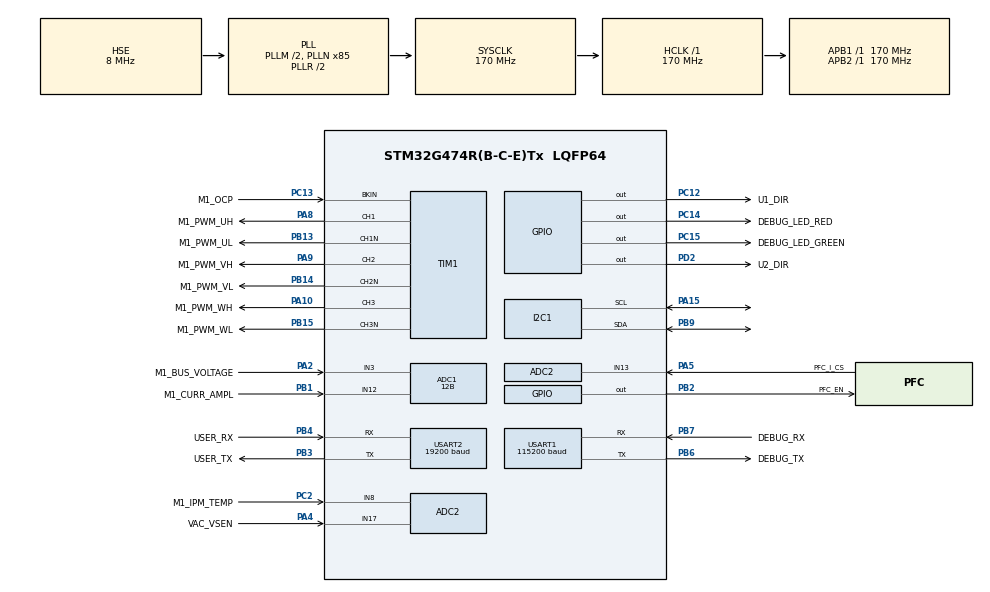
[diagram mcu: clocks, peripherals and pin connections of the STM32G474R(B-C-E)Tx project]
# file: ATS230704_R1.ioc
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ADC1.Channel-1\#ChannelRegularConversion=ADC_CHANNEL_3
ADC1.ClockPrescaler=ADC_CLOCK_ASYNC_DIV1
ADC1.ContinuousConvMode=DISABLE
ADC1.DMAContinuousRequests=DISABLE
ADC1.DataAlign=ADC_DATAALIGN_LEFT
ADC1.DiscontinuousConvMode=DISABLE
ADC1.EOCSelection=ADC_EOC_SINGLE_CONV
ADC1.EnableAnalogWatchDog1=false
ADC1.EnableAnalogWatchDog2=false
ADC1.EnableAnalogWatchDog3=false
ADC1.EnableInjectedConversion=ENABLE
ADC1.EnableRegularConversion=ENABLE
ADC1.ExternalTrigConv=ADC_SOFTWARE_START
ADC1.ExternalTrigConvEdge=ADC_EXTERNALTRIGCONVEDGE_NONE
ADC1.ExternalTrigInjecConv=ADC_EXTERNALTRIGINJEC_T1_TRGO
ADC1.ExternalTrigInjecConvEdge=ADC_EXTERNALTRIGINJECCONV_EDGE_RISINGFALLING
ADC1.InjNumberOfConversion=2
ADC1.InjectedChannel-1\#ChannelInjectedConversion=ADC_CHANNEL_12
ADC1.InjectedChannel-2\#ChannelInjectedConversion=ADC_CHANNEL_12
ADC1.InjectedConvMode=None
ADC1.InjectedOffset-1\#ChannelInjectedConversion=0
ADC1.InjectedOffset-2\#ChannelInjectedConversion=0
ADC1.InjectedOffsetNumber-1\#ChannelInjectedConversion=ADC_OFFSET_NONE
ADC1.InjectedOffsetNumber-2\#ChannelInjectedConversion=ADC_OFFSET_NONE
ADC1.InjectedRank-1\#ChannelInjectedConversion=1
ADC1.InjectedRank-2\#ChannelInjectedConversion=2
ADC1.InjectedSamplingTime-1\#ChannelInjectedConversion=ADC_SAMPLETIME_6CYCLES_5
ADC1.InjectedSamplingTime-2\#ChannelInjectedConversion=ADC_SAMPLETIME_6CYCLES_5
ADC1.LowPowerAutoWait=DISABLE
ADC1.NbrOfConversion=1
ADC1.NbrOfConversionFlag=1
ADC1.Offset-1\#ChannelRegularConversion=0
ADC1.OffsetNumber-1\#ChannelRegularConversion=ADC_OFFSET_NONE
ADC1.Overrun=ADC_OVR_DATA_PRESERVED
ADC1.Rank-1\#ChannelRegularConversion=1
ADC1.Resolution=ADC_RESOLUTION_12B
ADC1.SamplingTime-1\#ChannelRegularConversion=ADC_SAMPLETIME_640CYCLES_5
ADC1.ScanConvMode=ADC_SCAN_ENABLE
ADC1.master=1
ADC2.Channel-0\#ChannelRegularConversion=ADC_CHANNEL_8
ADC2.Channel-1\#ChannelRegularConversion=ADC_CHANNEL_13
ADC2.Channel-2\#ChannelRegularConversion=ADC_CHANNEL_17
ADC2.ClockPrescaler=ADC_CLOCK_ASYNC_DIV1
ADC2.ContinuousConvMode=ENABLE
ADC2.DMAContinuousRequests=ENABLE
ADC2.NbrOfConversion=3
ADC2.NbrOfConversionFlag=1
ADC2.OffsetNumber-0\#ChannelRegularConversion=ADC_OFFSET_NONE
ADC2.OffsetNumber-1\#ChannelRegularConversion=ADC_OFFSET_NONE
ADC2.OffsetNumber-2\#ChannelRegularConversion=ADC_OFFSET_NONE
ADC2.Rank-0\#ChannelRegularConversion=1
ADC2.Rank-1\#ChannelRegularConversion=2
ADC2.Rank-2\#ChannelRegularConversion=3
ADC2.SamplingTime-0\#ChannelRegularConversion=ADC_SAMPLETIME_2CYCLES_5
ADC2.SamplingTime-1\#ChannelRegularConversion=ADC_SAMPLETIME_2CYCLES_5
ADC2.SamplingTime-2\#ChannelRegularConversion=ADC_SAMPLETIME_2CYCLES_5
ADC3.Channel-0\#ChannelRegularConversion=ADC_CHANNEL_1
ADC3.NbrOfConversionFlag=1
ADC3.OffsetNumber-0\#ChannelRegularConversion=ADC_OFFSET_NONE
ADC3.Rank-0\#ChannelRegularConversion=1
ADC3.SamplingTime-0\#ChannelRegularConversion=ADC_SAMPLETIME_2CYCLES_5
ADC3.master=1
Dma.ADC2.5.Direction=DMA_PERIPH_TO_MEMORY
Dma.ADC2.5.EventEnable=DISABLE
Dma.ADC2.5.Instance=DMA1_Channel6
Dma.ADC2.5.MemDataAlignment=DMA_MDATAALIGN_WORD
Dma.ADC2.5.MemInc=DMA_MINC_ENABLE
Dma.ADC2.5.Mode=DMA_CIRCULAR
Dma.ADC2.5.PeriphDataAlignment=DMA_PDATAALIGN_WORD
Dma.ADC2.5.PeriphInc=DMA_PINC_DISABLE
Dma.ADC2.5.Polarity=HAL_DMAMUX_REQ_GEN_RISING
Dma.ADC2.5.Priority=DMA_PRIORITY_LOW
Dma.ADC2.5.RequestNumber=1
Dma.ADC2.5.SignalID=NONE
Dma.ADC2.5.SyncEnable=DISABLE
Dma.ADC2.5.SyncPolarity=HAL_DMAMUX_SYNC_NO_EVENT
Dma.ADC2.5.SyncRequestNumber=1
Dma.ADC2.5.SyncSignalID=NONE
Dma.Request0=TIM1_CH4
Dma.Request1=USART1_RX
Dma.Request2=USART1_TX
Dma.Request3=USART2_TX
Dma.Request4=USART2_RX
Dma.Request5=ADC2
Dma.TIM1_CH4.0.Direction=DMA_MEMORY_TO_PERIPH
Dma.TIM1_CH4.0.EventEnable=DISABLE
Dma.TIM1_CH4.0.Instance=DMA1_Channel1
Dma.TIM1_CH4.0.MemDataAlignment=DMA_MDATAALIGN_HALFWORD
Dma.TIM1_CH4.0.MemInc=DMA_MINC_ENABLE
Dma.TIM1_CH4.0.Mode=DMA_CIRCULAR
Dma.TIM1_CH4.0.PeriphDataAlignment=DMA_PDATAALIGN_HALFWORD
Dma.TIM1_CH4.0.PeriphInc=DMA_PINC_DISABLE
Dma.TIM1_CH4.0.Polarity=HAL_DMAMUX_REQ_GEN_RISING
Dma.TIM1_CH4.0.Priority=DMA_PRIORITY_HIGH
Dma.TIM1_CH4.0.RequestNumber=1
Dma.TIM1_CH4.0.SignalID=NONE
Dma.TIM1_CH4.0.SyncEnable=DISABLE
Dma.TIM1_CH4.0.SyncPolarity=HAL_DMAMUX_SYNC_NO_EVENT
Dma.TIM1_CH4.0.SyncRequestNumber=1
Dma.TIM1_CH4.0.SyncSignalID=NONE
Dma.USART1_RX.1.Direction=DMA_PERIPH_TO_MEMORY
Dma.USART1_RX.1.EventEnable=DISABLE
Dma.USART1_RX.1.Instance=DMA1_Channel2
Dma.USART1_RX.1.MemDataAlignment=DMA_MDATAALIGN_BYTE
Dma.USART1_RX.1.MemInc=DMA_MINC_ENABLE
Dma.USART1_RX.1.Mode=DMA_NORMAL
Dma.USART1_RX.1.PeriphDataAlignment=DMA_PDATAALIGN_BYTE
Dma.USART1_RX.1.PeriphInc=DMA_PINC_DISABLE
Dma.USART1_RX.1.Polarity=HAL_DMAMUX_REQ_GEN_RISING
Dma.USART1_RX.1.Priority=DMA_PRIORITY_LOW
Dma.USART1_RX.1.RequestNumber=1
Dma.USART1_RX.1.SignalID=NONE
Dma.USART1_RX.1.SyncEnable=DISABLE
Dma.USART1_RX.1.SyncPolarity=HAL_DMAMUX_SYNC_NO_EVENT
Dma.USART1_RX.1.SyncRequestNumber=1
Dma.USART1_RX.1.SyncSignalID=NONE
Dma.USART1_TX.2.Direction=DMA_MEMORY_TO_PERIPH
Dma.USART1_TX.2.EventEnable=DISABLE
Dma.USART1_TX.2.Instance=DMA1_Channel3
Dma.USART1_TX.2.MemDataAlignment=DMA_MDATAALIGN_BYTE
Dma.USART1_TX.2.MemInc=DMA_MINC_ENABLE
Dma.USART1_TX.2.Mode=DMA_NORMAL
Dma.USART1_TX.2.PeriphDataAlignment=DMA_PDATAALIGN_BYTE
Dma.USART1_TX.2.PeriphInc=DMA_PINC_DISABLE
Dma.USART1_TX.2.Polarity=HAL_DMAMUX_REQ_GEN_RISING
Dma.USART1_TX.2.Priority=DMA_PRIORITY_LOW
Dma.USART1_TX.2.RequestNumber=1
Dma.USART1_TX.2.SignalID=NONE
Dma.USART1_TX.2.SyncEnable=DISABLE
Dma.USART1_TX.2.SyncPolarity=HAL_DMAMUX_SYNC_NO_EVENT
Dma.USART1_TX.2.SyncRequestNumber=1
Dma.USART1_TX.2.SyncSignalID=NONE
Dma.USART2_RX.4.Direction=DMA_PERIPH_TO_MEMORY
Dma.USART2_RX.4.EventEnable=DISABLE
Dma.USART2_RX.4.Instance=DMA1_Channel5
Dma.USART2_RX.4.MemDataAlignment=DMA_MDATAALIGN_BYTE
Dma.USART2_RX.4.MemInc=DMA_MINC_ENABLE
Dma.USART2_RX.4.Mode=DMA_CIRCULAR
Dma.USART2_RX.4.PeriphDataAlignment=DMA_PDATAALIGN_BYTE
Dma.USART2_RX.4.PeriphInc=DMA_PINC_DISABLE
Dma.USART2_RX.4.Polarity=HAL_DMAMUX_REQ_GEN_RISING
Dma.USART2_RX.4.Priority=DMA_PRIORITY_LOW
Dma.USART2_RX.4.RequestNumber=1
Dma.USART2_RX.4.SignalID=NONE
Dma.USART2_RX.4.SyncEnable=DISABLE
Dma.USART2_RX.4.SyncPolarity=HAL_DMAMUX_SYNC_NO_EVENT
Dma.USART2_RX.4.SyncRequestNumber=1
Dma.USART2_RX.4.SyncSignalID=NONE
Dma.USART2_TX.3.Direction=DMA_MEMORY_TO_PERIPH
Dma.USART2_TX.3.EventEnable=DISABLE
Dma.USART2_TX.3.Instance=DMA1_Channel4
Dma.USART2_TX.3.MemDataAlignment=DMA_MDATAALIGN_BYTE
Dma.USART2_TX.3.MemInc=DMA_MINC_ENABLE
Dma.USART2_TX.3.Mode=DMA_NORMAL
Dma.USART2_TX.3.PeriphDataAlignment=DMA_PDATAALIGN_BYTE
Dma.USART2_TX.3.PeriphInc=DMA_PINC_DISABLE
Dma.USART2_TX.3.Polarity=HAL_DMAMUX_REQ_GEN_RISING
Dma.USART2_TX.3.Priority=DMA_PRIORITY_LOW
Dma.USART2_TX.3.RequestNumber=1
Dma.USART2_TX.3.SignalID=NONE
Dma.USART2_TX.3.SyncEnable=DISABLE
Dma.USART2_TX.3.SyncPolarity=HAL_DMAMUX_SYNC_NO_EVENT
Dma.USART2_TX.3.SyncRequestNumber=1
Dma.USART2_TX.3.SyncSignalID=NONE
ExtraMW=MotorControl
ExtraMW.MotorControl.Config=MotorControl
ExtraMW.MotorControl.Mode=MotorControl
ExtraMW.MotorControl.Root=MCSDK_v6.2.0-Full/MotorControl
ExtraMW.MotorControl.Template=templates
FREERTOS.Tasks01=Print_Task,8,256,StartPrintTask,As weak,NULL,Static,PrintTaskBuffer,PrintTaskControlBlock;Modbus_Task,40,128,StartModbusTask,As weak,NULL,Static,Modbus_TaskBuffer,Modbus_TaskControlBlock;Sensor_TasK,24,128,StartSensorTask,As weak,NULL,Static,Sensor_TasKBuffer,Sensor_TasKControlBlock;PowerCTRLTask,40,128,StartPowerCTRLTask,As weak,NULL,Static,PowerCTRLTaskBuffer,PowerCTRLTaskControlBlock
FREERTOS.configCHECK_FOR_STACK_OVERFLOW=2
FREERTOS.configUSE_NEWLIB_REENTRANT=1
I2C1.Timing=0x30A0A7FB
Mcu.Family=STM32G4
Mcu.Name=STM32G474R(B-C-E)Tx
Mcu.Package=LQFP64
MotorControl.ADC_AHBPERIPH=RCC_AHBPeriph_ADC1
MotorControl.ADC_CLOCK_WB_DIV=1
MotorControl.ADC_PERIPH=ADC1
MotorControl.ADC_REFERENCE_VOLTAGE=3.3
MotorControl.BOARD=NUCLEO-G474RE
MotorControl.BUS_VOLTAGE_READING=true
MotorControl.CCMRAM_ENABLED=false
MotorControl.CLOCK_FREQUENCY=CPU_CLK_170_MHZ
MotorControl.CLOCK_SOURCE=EXTERNAL
MotorControl.CPU_CLK_170_MHZ=true
MotorControl.CTLBOARD_NAME=NUCLEO-G474RE
MotorControl.CUBE_MX_VER=6.9.2
MotorControl.CURRENT_READING_TOPOLOGY=SINGLE_SHUNT
MotorControl.CURR_SAMPLING_TIME=6
MotorControl.DBG_MCU_LOAD_MEASURE=true
MotorControl.DEBUG_DAC_FUNCTIONALITY_EN=false
MotorControl.DISSIPATIVE_BRAKE_POLARITY=DOUT_ACTIVE_HIGH
MotorControl.DRIVES_NUMBER_SELECTION=SINGLEDRIVE
MotorControl.DRIVE_NUMBER=1
MotorControl.DRIVE_TYPE=FOC
MotorControl.EMERGENCY_STOP_GPIO_PIN=LL_GPIO_PIN_13
MotorControl.EMERGENCY_STOP_GPIO_PORT=GPIOC
MotorControl.ENCODER_AVAILABLE=false
MotorControl.ENCODER_PPR=400
MotorControl.EXT_CLK_8_MHZ=true
MotorControl.EXT_CLOCK_FREQUENCY=EXT_CLK_8_MHZ
MotorControl.FEEDBACK_NET_FILTERING=false
MotorControl.HALL_SENSORS_AVAILABLE=false
MotorControl.HIGH_SIDE_IDLE_STATE=false
MotorControl.HWV_CS=SingleShunt_AmplifiedCurrents
MotorControl.HWV_OCP=OnPowerStageOCP
MotorControl.HWV_PWM=DrivingHighAndLowSides
MotorControl.HW_COMPLEMENTED_LOW_SIDE=false
MotorControl.HW_DEAD_TIME_NS=8000
MotorControl.IPs=CORDIC,SYS,NVIC,RCC,MotorControl,TIM1,ADC1,USART1,DMA
MotorControl.LOW_MEMORY_FOOTPRINT_REG=false
MotorControl.LOW_SIDE_IDLE_STATE=false
MotorControl.LOW_SIDE_SIGNALS_ENABLING=LS_PWM_TIMER
MotorControl.M1_AMPLIFICATION_GAIN=2.941176471
MotorControl.M1_ANGC={-773,-2329,-3874,-5379,-6858,-8285,-9684,-11001}
MotorControl.M1_AUXILIARY_SPEED_SENSOR=NONE
MotorControl.M1_BEMF_CONSISTENCY_GAIN=64
MotorControl.M1_BEMF_CONSISTENCY_TOL=64
MotorControl.M1_BOARD_MAX_CURRENT=25.0
MotorControl.M1_BUS_VOLTAGE_READING=true
MotorControl.M1_CONSTANT1_D=164333
MotorControl.M1_CONSTANT1_Q=234761
MotorControl.M1_CONSTANT2_QD=42544
MotorControl.M1_CS_ADC_NUM=1
MotorControl.M1_CS_ADC_PHASE_SHARED=NONE
MotorControl.M1_CS_ADC_U=ADC1
MotorControl.M1_CS_CHANNEL_U=12
MotorControl.M1_CURRENT_AMPLIFICATION_TOPO=EXTERNAL
MotorControl.M1_CURRENT_SENSING_TOPO=SINGLE_SHUNT_PHASE_SHIFT
MotorControl.M1_CURR_SAMPLING_TIME=6
MotorControl.M1_DBG_OPEN_LOOP_ENABLE=false
MotorControl.M1_DC_CURRENT_RS_MEAS=20.0
MotorControl.M1_DEFAULT_CONTROL_MODE=STC_SPEED_MODE
MotorControl.M1_DEFAULT_FLUX_COMPONENT=0
MotorControl.M1_DEFAULT_TARGET_SPEED_RPM=1300
MotorControl.M1_DEFAULT_TORQUE_COMPONENT=0
MotorControl.M1_DISCONTINUOUS_PWM=false
MotorControl.M1_DISSIPATIVE_BRAKE_POLARITY=DOUT_ACTIVE_HIGH
MotorControl.M1_DP_TOPOLOGY=NONE
MotorControl.M1_DRIVE_TYPE=FOC
MotorControl.M1_ENABLE_SL_ALGO_FROM_PHASE=4
MotorControl.M1_ENCODER_PPR=400
MotorControl.M1_F1=16384
MotorControl.M1_F2=8192
MotorControl.M1_FEED_FORWARD_CURRENT_REG_ENABLING=false
MotorControl.M1_FLUX_WEAKENING_ENABLING=true
MotorControl.M1_FW_KIDIV=32768
MotorControl.M1_FW_KI_GAIN=5000
MotorControl.M1_FW_KPDIV=32768
MotorControl.M1_FW_KP_GAIN=3000
MotorControl.M1_FW_VOLTAGE_REF=985
MotorControl.M1_GAIN1=-24494
MotorControl.M1_GAIN2=24912
MotorControl.M1_HALL_PHASE_SHIFT=300
MotorControl.M1_HALL_SENSORS_PLACEMENT=DEGREES_120
MotorControl.M1_HIGH_SIDE_IDLE_STATE=false
MotorControl.M1_HW_DEAD_TIME_NS=8000
MotorControl.M1_ICL_ENABLED=false
MotorControl.M1_ID_DEMAG=-25
MotorControl.M1_IQMAX=24.58797507430251
MotorControl.M1_LDLQ_RATIO=0.700
MotorControl.M1_LOW_SIDE_IDLE_STATE=false
MotorControl.M1_LOW_SIDE_SIGNALS_ENABLING=LS_PWM_TIMER
MotorControl.M1_LS=0.00466
MotorControl.M1_MAX_APPLICATION_SPEED=5400
MotorControl.M1_MAX_MODULATION_INDEX=100
MotorControl.M1_MIN_APPLICATION_SPEED=0
MotorControl.M1_MOTOR_MAX_SPEED_RPM=5400
MotorControl.M1_MOTOR_NAME=BTH420SDPC9EQA
MotorControl.M1_MOTOR_RATED_FLUX=1.055730079
MotorControl.M1_MOTOR_VOLTAGE_CONSTANT=43.1
MotorControl.M1_MTPA_ENABLING=true
MotorControl.M1_NB_CONSECUTIVE_TESTS=3
MotorControl.M1_NOMINAL_BUS_VOLTAGE_V=400
MotorControl.M1_NOMINAL_CURRENT=20.0
MotorControl.M1_OBS_MINIMUM_SPEED_RPM=850
MotorControl.M1_OCP_BKIN_FILTER=3
MotorControl.M1_OCP_BKIN_MODE=EXT_MODE
MotorControl.M1_OCP_BKIN_POLARITY=EMSTOP_ACTIVE_LOW
MotorControl.M1_OCP_DESTINATION=TIM_BKIN
MotorControl.M1_OCP_TOPOLOGY=EXTERNAL
MotorControl.M1_OFST={0,144,432,853,1404,2069,2851,3709}
MotorControl.M1_OVERMODULATION=false
MotorControl.M1_OVP_THRESHOLD_LOW=400
MotorControl.M1_OV_VOLTAGE_PROT_ENABLING=false
MotorControl.M1_PHASE1_DURATION=300
MotorControl.M1_PHASE1_FINAL_CURRENT=5
MotorControl.M1_PHASE1_FINAL_SPEED_RPM=0
MotorControl.M1_PHASE2_DURATION=500
MotorControl.M1_PHASE2_FINAL_CURRENT=5
MotorControl.M1_PHASE2_FINAL_SPEED_RPM=0
MotorControl.M1_PHASE3_DURATION=0
MotorControl.M1_PHASE3_FINAL_CURRENT=5
MotorControl.M1_PHASE3_FINAL_SPEED_RPM=500
MotorControl.M1_PHASE4_DURATION=5000
MotorControl.M1_PHASE4_FINAL_CURRENT=5
MotorControl.M1_PHASE4_FINAL_SPEED_RPM=900
MotorControl.M1_PHASE5_DURATION=20000
MotorControl.M1_PHASE5_FINAL_CURRENT=5
MotorControl.M1_PHASE5_FINAL_SPEED_RPM=1300
MotorControl.M1_PID_FLUX_KD_DEFAULT=100
MotorControl.M1_PID_FLUX_KI_DEFAULT=63
MotorControl.M1_PID_FLUX_KP_DEFAULT=1703
MotorControl.M1_PID_SPEED_KD_DEFAULT=0
MotorControl.M1_PID_SPEED_KI_DEFAULT=811
MotorControl.M1_PID_SPEED_KP_DEFAULT=3166
MotorControl.M1_PID_TORQUE_KD_DEFAULT=100
MotorControl.M1_PID_TORQUE_KI_DEFAULT=63
MotorControl.M1_PID_TORQUE_KP_DEFAULT=2361
MotorControl.M1_PLL_KI_GAIN=64
MotorControl.M1_PLL_KP_GAIN=718
MotorControl.M1_POLE_PAIR_NUM=2
MotorControl.M1_POSITION_CTRL_ENABLING=false
MotorControl.M1_POTENTIOMETER_ENABLE=false
MotorControl.M1_POWERBOARD_NAME=ATS230704-R1
MotorControl.M1_PWM_CHARGE_BOOT_CAP_DUTY_CYCLES=0.000
MotorControl.M1_PWM_CHARGE_BOOT_CAP_MS=10
MotorControl.M1_PWM_DRIVER_PN=L6390D
MotorControl.M1_PWM_FREQUENCY=8000
MotorControl.M1_PWM_TIMER_BRK_IRQ=TIM1_BRK_TIM15
MotorControl.M1_PWM_TIMER_SELECTION=PWM_TIM1
MotorControl.M1_PWM_TIMER_UP_IRQ=TIM1_UP_TIM16
MotorControl.M1_REGULATION_EXECUTION_RATE=1
MotorControl.M1_RS=0.25
MotorControl.M1_RSHUNT=0.01175
MotorControl.M1_SEGDIV=3052
MotorControl.M1_SHARED_SIGNAL_ENABLE=false
MotorControl.M1_SPD_DIFFERENTIAL_TERM_ENABLING=false
MotorControl.M1_SPEED_BAND_LOWER_LIMIT=16
MotorControl.M1_SPEED_BAND_UPPER_LIMIT=22
MotorControl.M1_SPEED_FEEDBACK_CHECK=true
MotorControl.M1_SPEED_LOOP_FREQUENCY_HZ=500
MotorControl.M1_SPEED_SENSOR=STO_PLL
MotorControl.M1_SP_KDDIV=16
MotorControl.M1_SP_KIDIV=16384
MotorControl.M1_SP_KPDIV=128
MotorControl.M1_SS_MEAS_ERRORS_BEFORE_FAULTS=100
MotorControl.M1_STARTING_ANGLE_DEG=0
MotorControl.M1_STO_FIFO_DEPTH_01HZ=64
MotorControl.M1_STO_FIFO_DEPTH_DPP=64
MotorControl.M1_SW_DEADTIME_NS=4000
MotorControl.M1_TEMPERATURE_READING=false
MotorControl.M1_TF_KDDIV=8192
MotorControl.M1_TF_KIDIV=16384
MotorControl.M1_TF_KPDIV=4096
MotorControl.M1_TNOISE_NS=2500
MotorControl.M1_TRANSITION_DURATION=0
MotorControl.M1_TRISE_NS=2500
MotorControl.M1_USE_INTERNAL_OPAMP=false
MotorControl.M1_UV_VOLTAGE_PROT_ENABLING=false
MotorControl.M1_VARIANCE_THRESHOLD=0.25
MotorControl.M1_VBUS_ADC=ADC1
MotorControl.M1_VBUS_ADC_SAMPLING_TIME=640
MotorControl.M1_VBUS_CHANNEL=ADC_CHANNEL_3
MotorControl.M1_VBUS_PARTITIONING_FACTOR=0.006493506493506494
MotorControl.MAX_READABLE_CURRENT=23.179
MotorControl.MCP_ASPEP_OVER_UART=true
MotorControl.MCP_ASYNC_EN=false
MotorControl.MCP_ASYNC_OVER_ASPEP_EN=false
MotorControl.MCP_ASYNC_OVER_UART_A_EN=false
MotorControl.MCP_DMACH_RX_UART_A=2
MotorControl.MCP_DMACH_TX_UART_A=3
MotorControl.MCP_DMA_RX_UART_A=DMA1
MotorControl.MCP_DMA_TX_UART_A=DMA1
MotorControl.MCP_EN=true
MotorControl.MCP_IRQ_HANDLER_DMA_RX_UART_A=DMA1_Channel2_IRQHandler
MotorControl.MCP_IRQ_HANDLER_UART_A=USART1_IRQHandler
MotorControl.MCP_OVER_ASPEP_EN=true
MotorControl.MCP_OVER_STLNK_EN=false
MotorControl.MCP_OVER_UART_A_EN=true
MotorControl.MCP_OVER_UART_B_EN=false
MotorControl.MCP_RX_SYNC_PAYLOAD_MAX=128
MotorControl.MCP_TX_SYNC_PAYLOAD_MAX=128
MotorControl.MCU=STM32G474RE
MotorControl.MCU_FAMILY=STM32G4
MotorControl.MCU_LINE=STM32G4x4
MotorControl.MCU_NAME=STM32G474R(B-C-E)Tx
MotorControl.MCU_PACKAGE=LQFP64
MotorControl.MCU_TYPE=STM32G474RE
MotorControl.MCU_USERNAME=STM32G474RETx
MotorControl.MC_WORKBENCH_VERSION=6.2.0
MotorControl.MOTOR_PROFILER=false
MotorControl.MOTOR_TYPE=PMSM
MotorControl.OV_VOLTAGE_PROT_ENABLING=false
MotorControl.PHASE_CURRENTS_ADC=ADC1
MotorControl.PHASE_CURRENTS_CHANNEL=ADC_CHANNEL_12
MotorControl.PHASE_CURRENTS_GPIO_PIN=LL_GPIO_PIN_1
MotorControl.PHASE_CURRENTS_GPIO_PORT=GPIOB
MotorControl.PHASE_UH_GPIO_PIN=LL_GPIO_PIN_8
MotorControl.PHASE_UH_GPIO_PORT=GPIOA
MotorControl.PHASE_UH_POLARITY=H_ACTIVE_HIGH
MotorControl.PHASE_UL_GPIO_PIN=LL_GPIO_PIN_13
MotorControl.PHASE_UL_GPIO_PORT=GPIOB
MotorControl.PHASE_UL_POLARITY=L_ACTIVE_HIGH
MotorControl.PHASE_VH_GPIO_PIN=LL_GPIO_PIN_9
MotorControl.PHASE_VH_GPIO_PORT=GPIOA
MotorControl.PHASE_VH_POLARITY=H_ACTIVE_HIGH
MotorControl.PHASE_VL_GPIO_PIN=LL_GPIO_PIN_14
MotorControl.PHASE_VL_GPIO_PORT=GPIOB
MotorControl.PHASE_VL_POLARITY=L_ACTIVE_HIGH
MotorControl.PHASE_WH_GPIO_PIN=LL_GPIO_PIN_10
MotorControl.PHASE_WH_GPIO_PORT=GPIOA
MotorControl.PHASE_WH_POLARITY=H_ACTIVE_HIGH
MotorControl.PHASE_WL_GPIO_PIN=LL_GPIO_PIN_15
MotorControl.PHASE_WL_GPIO_PORT=GPIOB
MotorControl.PHASE_WL_POLARITY=L_ACTIVE_HIGH
MotorControl.POTENTIOMETER_READING=false
MotorControl.PWM_FREQUENCY=10000
MotorControl.PWM_TIMER_SELECTION=PWM_TIM1
MotorControl.REGULATION_EXECUTION_RATE=1
MotorControl.RTOS=NONE
MotorControl.R_BRAKE_GPIO_PIN=LL_GPIO_PIN_11
MotorControl.R_BRAKE_GPIO_PORT=GPIOC
MotorControl.SINGLEDRIVE=true
MotorControl.SINGLE_SHUNT=true
MotorControl.SPD_DIFFERENTIAL_TERM_ENABLING=false
MotorControl.SPEED_SENSOR_SELECTION=STATE_OBSERVER_PLL
MotorControl.START_STOP_BTN=false
MotorControl.STATE_OBSERVER_PLL=true
MotorControl.STM32G474RE=true
MotorControl.SW_DEADTIME_NS=3000
MotorControl.TEMPERATURE_READING=false
MotorControl.TFDIFFERENTIAL_TERM_ENABLING=false
MotorControl.TRISE_NS=4500
MotorControl.USART_RX_GPIO_PIN=LL_GPIO_PIN_7
MotorControl.USART_RX_GPIO_PORT=GPIOB
MotorControl.USART_SELECTION=USE_USART1
MotorControl.USART_SELECTION_A=USART1
MotorControl.USART_SPEED=115200
MotorControl.USART_TX_GPIO_PIN=LL_GPIO_PIN_6
MotorControl.USART_TX_GPIO_PORT=GPIOB
MotorControl.USE_3OPAMPS=false
MotorControl.USE_INTERNAL_OPAMP=false
MotorControl.UV_VOLTAGE_PROT_ENABLING=false
MotorControl.VBUS_ADC=ADC1
MotorControl.VBUS_ADC_SAMPLING_TIME=640
MotorControl.VBUS_CHANNEL=ADC_CHANNEL_3
MotorControl.VBUS_GPIO_PIN=LL_GPIO_PIN_2
MotorControl.VBUS_GPIO_PORT=GPIOA
MotorControl.WB_UI_CUTOFF_FREQUENCY=1500
MotorControl.WB_UI_ENCODER_HAS_INDEX_PIN=false
MotorControl.WB_UI_FLUX_TARGET=0
MotorControl.WB_UI_FRICTION=666
MotorControl.WB_UI_INERTIA=666
MotorControl.WB_UI_MAGNETIC_STRUCTURE=I-PMSM
MotorControl.WB_UI_MAX_CURRENT=25.0
MotorControl.WB_UI_MAX_NOMINAL_DC_VOLTAGE=400
MotorControl.WB_UI_MOTOR_DESCRIPTION=Motor high voltage
MotorControl.WB_UI_OCP_DISABLING_ENABLE=false
MotorControl.WB_UI_OCP_THRESHOLD=24
MotorControl.WB_UI_PW_BOARD_MAX_RATED_CURRENT=25.0
MotorControl.WB_UI_PW_BOARD_MAX_VOLTAGE=400
MotorControl.WB_UI_PW_BOARD_MIN_VOLTAGE=18
MotorControl.WB_UI_VPOL=1.65
MotorControl.WB_to_Mx_template_version=23-09-08
MotorControl.WB_to_Mx_version=6.2.0
NVIC.ADC1_2_IRQn=true\:2\:0\:true\:true\:false\:4\:false\:true\:true\:true
NVIC.DMA1_Channel1_IRQn=true\:0\:0\:true\:true\:false\:2\:false\:true\:true\:true
NVIC.DMA1_Channel2_IRQn=true\:3\:0\:true\:true\:false\:3\:false\:true\:true\:true
NVIC.DMA1_Channel4_IRQn=true\:3\:0\:true\:false\:true\:false\:true\:true\:true
NVIC.DMA1_Channel5_IRQn=true\:3\:0\:true\:false\:true\:false\:true\:true\:true
NVIC.PriorityGroup=NVIC_PRIORITYGROUP_4
NVIC.TIM1_BRK_TIM15_IRQn=true\:4\:0\:true\:true\:false\:5\:false\:true\:true\:true
NVIC.TIM1_UP_TIM16_IRQn=true\:0\:0\:true\:true\:false\:6\:false\:true\:true\:true
NVIC.TIM6_DAC_IRQn=true\:15\:0\:true\:true\:true\:7\:true\:true\:true\:true
NVIC.USART1_IRQn=true\:3\:0\:true\:true\:false\:1\:false\:true\:true\:true
NVIC.USART2_IRQn=true\:3\:0\:true\:false\:true\:false\:true\:true\:true
PA10.GPIO_Label=M1_PWM_WH
PA10.GPIO_PuPd=GPIO_PULLDOWN
PA10.GPIO_Speed=GPIO_SPEED_FREQ_HIGH
PA10.Signal=S_TIM1_CH3
PA13.GPIO_Label=TMS
PA13.Mode=Serial_Wire
PA13.Signal=SYS_JTMS-SWDIO
PA14.GPIO_Label=TCK
PA14.Mode=Serial_Wire
PA14.Signal=SYS_JTCK-SWCLK
PA15.Mode=I2C
PA15.Signal=I2C1_SCL
PA2.GPIO_Label=M1_BUS_VOLTAGE
PA2.Mode=IN3-Single-Ended
PA2.Signal=ADC1_IN3
PA4.GPIO_Label=VAC_VSEN
PA4.Mode=IN17-Single-Ended
PA4.Signal=ADC2_IN17
PA5.GPIO_Label=PFC_I_CS
PA5.Mode=IN13-Single-Ended
PA5.Signal=ADC2_IN13
PA8.GPIO_Label=M1_PWM_UH
PA8.GPIO_PuPd=GPIO_PULLDOWN
PA8.GPIO_Speed=GPIO_SPEED_FREQ_HIGH
PA8.Signal=S_TIM1_CH1
PA9.GPIO_Label=M1_PWM_VH
PA9.GPIO_PuPd=GPIO_PULLDOWN
PA9.GPIO_Speed=GPIO_SPEED_FREQ_HIGH
PA9.Signal=S_TIM1_CH2
PB1.GPIO_Label=M1_CURR_AMPL
PB1.Signal=SharedAnalog_PB1
PB13.GPIO_Label=M1_PWM_UL
PB13.GPIO_PuPd=GPIO_PULLDOWN
PB13.GPIO_Speed=GPIO_SPEED_FREQ_HIGH
PB13.Mode=PWM Generation1 CH1 CH1N
PB13.Signal=TIM1_CH1N
PB14.GPIO_Label=M1_PWM_VL
PB14.GPIO_PuPd=GPIO_PULLDOWN
PB14.GPIO_Speed=GPIO_SPEED_FREQ_HIGH
PB14.Mode=PWM Generation2 CH2 CH2N
PB14.Signal=TIM1_CH2N
PB15.GPIO_Label=M1_PWM_WL
PB15.GPIO_PuPd=GPIO_PULLDOWN
PB15.GPIO_Speed=GPIO_SPEED_FREQ_HIGH
PB15.Mode=PWM Generation3 CH3 CH3N
PB15.Signal=TIM1_CH3N
PB2.GPIO_Label=PFC_EN
PB2.Signal=GPIO_Output
PB3.GPIO_Label=USER_TX
PB3.Mode=Asynchronous
PB3.Signal=USART2_TX
PB4.GPIO_Label=USER_RX
PB4.Mode=Asynchronous
PB4.Signal=USART2_RX
PB6.GPIO_Label=DEBUG_TX
PB6.GPIO_Mode=GPIO_MODE_AF_PP
PB6.GPIO_PuPd=GPIO_NOPULL
PB6.GPIO_Speed=GPIO_SPEED_FREQ_LOW
PB6.Mode=Asynchronous
PB6.Signal=USART1_TX
PB7.GPIO_Label=DEBUG_RX
PB7.GPIO_Mode=GPIO_MODE_AF_PP
PB7.GPIO_PuPd=GPIO_NOPULL
PB7.GPIO_Speed=GPIO_SPEED_FREQ_LOW
PB7.Mode=Asynchronous
PB7.Signal=USART1_RX
PB9.Mode=I2C
PB9.Signal=I2C1_SDA
PC12.GPIO_Label=U1_DIR
PC12.Signal=GPIO_Output
PC13.GPIO_Label=M1_OCP
PC13.GPIO_PuPd=GPIO_PULLUP
PC13.Mode=Activate-Break-Input
PC13.Signal=TIM1_BKIN
PC14-OSC32_IN.GPIO_Label=DEBUG_LED_RED
PC14-OSC32_IN.Signal=GPIO_Output
PC15-OSC32_OUT.GPIO_Label=DEBUG_LED_GREEN
PC15-OSC32_OUT.Signal=GPIO_Output
PC2.GPIO_Label=M1_IPM_TEMP
PC2.Mode=IN8-Single-Ended
PC2.Signal=ADC2_IN8
PD2.GPIO_Label=U2_DIR
PD2.Signal=GPIO_Output
PF0-OSC_IN.Mode=HSE-External-Oscillator
PF0-OSC_IN.Signal=RCC_OSC_IN
PF1-OSC_OUT.Mode=HSE-External-Oscillator
PF1-OSC_OUT.Signal=RCC_OSC_OUT
ProjectManager.HeapSize=0x200
ProjectManager.StackSize=0x400
ProjectManager.TargetToolchain=STM32CubeIDE
RCC.ADC12CLockSelection=RCC_ADC12CLKSOURCE_PLL
RCC.ADC12Freq_Value=42500000
RCC.ADC345CLockSelection=RCC_ADC345CLKSOURCE_PLL
RCC.ADC345Freq_Value=42500000
RCC.AHBFreq_Value=170000000
RCC.APB1Freq_Value=170000000
RCC.APB1TimFreq_Value=170000000
RCC.APB2Freq_Value=170000000
RCC.APB2TimFreq_Value=170000000
RCC.CK48CLockSelection=RCC_USBCLKSOURCE_PLL
RCC.CortexFreq_Value=170000000
RCC.EXTERNAL_CLOCK_VALUE=12288000
RCC.HCLKFreq_Value=170000000
RCC.HSE_VALUE=8000000
RCC.HSI48_VALUE=48000000
RCC.HSI_VALUE=16000000
RCC.LSE_VALUE=32768
RCC.PLLM=RCC_PLLM_DIV2
RCC.PLLN=85
RCC.PLLP=RCC_PLLP_DIV8
RCC.PLLSourceVirtual=RCC_PLLSOURCE_HSE
RCC.PREFETCH_ENABLE=1
RCC.SYSCLKFreq_VALUE=170000000
RCC.SYSCLKSource=RCC_SYSCLKSOURCE_PLLCLK
RCC.USBFreq_Value=170000000
RCC.VCOOutputFreq_Value=340000000
SH.S_TIM1_CH1.0=TIM1_CH1,PWM Generation1 CH1 CH1N
SH.S_TIM1_CH2.0=TIM1_CH2,PWM Generation2 CH2 CH2N
SH.S_TIM1_CH3.0=TIM1_CH3,PWM Generation3 CH3 CH3N
SH.SharedAnalog_PB1.0=ADC1_IN12,IN12-Single-Ended
SH.SharedAnalog_PB1.1=ADC3_IN1,IN1-Single-Ended
TIM1.AutoReloadPreload=TIM_AUTORELOAD_PRELOAD_DISABLE
TIM1.AutomaticOutput=TIM_AUTOMATICOUTPUT_DISABLE
TIM1.Break2Filter=3
TIM1.Break2Polarity=TIM_BREAK2POLARITY_HIGH
TIM1.Break2State=TIM_BREAK2_DISABLE
TIM1.BreakFilter=3
TIM1.BreakPolarity=TIM_BREAKPOLARITY_HIGH
TIM1.BreakState=TIM_BREAK_ENABLE
TIM1.Channel=TIM_CHANNEL_6
TIM1.Channel-PWM\ Generation1\ CH1\ CH1N=TIM_CHANNEL_1
TIM1.Channel-PWM\ Generation2\ CH2\ CH2N=TIM_CHANNEL_2
TIM1.Channel-PWM\ Generation3\ CH3\ CH3N=TIM_CHANNEL_3
TIM1.Channel-PWM\ Generation4\ No\ Output=TIM_CHANNEL_4
TIM1.Channel-PWM\ Generation5\ No\ Output=TIM_CHANNEL_5
TIM1.Channel-PWM\ Generation6\ No\ Output=TIM_CHANNEL_6
TIM1.ClearInputSource=TIM_CLEARINPUTSOURCE_NONE
TIM1.ClockDivision=TIM_CLOCKDIVISION_DIV2
TIM1.CounterMode=TIM_COUNTERMODE_CENTERALIGNED2
TIM1.DeadTime=((DEAD_TIME_COUNTS) / 2)
TIM1.LockLevel=TIM_LOCKLEVEL_OFF
TIM1.OC1Preload_PWM=ENABLE
TIM1.OC2Preload_PWM=ENABLE
TIM1.OC3Preload_PWM=ENABLE
TIM1.OC4Preload_PWM=ENABLE
TIM1.OC5Preload_PWM=ENABLE
TIM1.OC6Preload_PWM=ENABLE
TIM1.OCFastMode_PWM=TIM_OCFAST_DISABLE
TIM1.OCIdleState_1=TIM_OCIDLESTATE_RESET
TIM1.OCIdleState_2=TIM_OCIDLESTATE_RESET
TIM1.OCIdleState_3=TIM_OCIDLESTATE_RESET
TIM1.OCIdleState_4=TIM_OCIDLESTATE_RESET
TIM1.OCIdleState_5=TIM_OCIDLESTATE_RESET
TIM1.OCIdleState_6=TIM_OCIDLESTATE_RESET
TIM1.OCMode_PWM-PWM\ Generation1\ CH1\ CH1N=TIM_OCMODE_PWM1
TIM1.OCMode_PWM-PWM\ Generation2\ CH2\ CH2N=TIM_OCMODE_PWM1
TIM1.OCMode_PWM-PWM\ Generation3\ CH3\ CH3N=TIM_OCMODE_PWM1
TIM1.OCMode_PWM-PWM\ Generation4\ No\ Output=TIM_OCMODE_PWM2
TIM1.OCMode_PWM-PWM\ Generation5\ No\ Output=TIM_OCMODE_PWM2
TIM1.OCMode_PWM-PWM\ Generation6\ No\ Output=TIM_OCMODE_PWM2
TIM1.OCNIdleState_1=TIM_OCNIDLESTATE_RESET
TIM1.OCNIdleState_2=TIM_OCNIDLESTATE_RESET
TIM1.OCNIdleState_3=TIM_OCNIDLESTATE_RESET
TIM1.OCNPolarity_1=TIM_OCNPOLARITY_HIGH
TIM1.OCNPolarity_2=TIM_OCNPOLARITY_HIGH
TIM1.OCNPolarity_3=TIM_OCNPOLARITY_HIGH
TIM1.OCPolarity_1=TIM_OCPOLARITY_HIGH
TIM1.OCPolarity_2=TIM_OCPOLARITY_HIGH
TIM1.OCPolarity_3=TIM_OCPOLARITY_HIGH
TIM1.OCPolarity_4=TIM_OCPOLARITY_HIGH
TIM1.OCPolarity_5=TIM_OCPOLARITY_HIGH
TIM1.OCPolarity_6=TIM_OCPOLARITY_HIGH
TIM1.OffStateIDLEMode=TIM_OSSI_ENABLE
TIM1.OffStateRunMode=TIM_OSSR_ENABLE
TIM1.PeriodNoDither=((PWM_PERIOD_CYCLES) / 2)
TIM1.Prescaler=((TIM_CLOCK_DIVIDER) - 1)
TIM1.PulseNoDither_1=((PWM_PERIOD_CYCLES) / 4)
TIM1.PulseNoDither_2=((PWM_PERIOD_CYCLES) / 4)
TIM1.PulseNoDither_3=((PWM_PERIOD_CYCLES) / 4)
TIM1.PulseNoDither_4=(((PWM_PERIOD_CYCLES) / 2) - (HTMIN))
TIM1.PulseNoDither_5=(((PWM_PERIOD_CYCLES) / 2) + 1)
TIM1.PulseNoDither_6=(((PWM_PERIOD_CYCLES) / 2) + 1)
TIM1.RepetitionCounter=(REP_COUNTER)
TIM1.SourceBRK2DigInput=TIM_BREAKINPUTSOURCE_DISABLE
TIM1.SourceBRKDigInput=TIM_BREAKINPUTSOURCE_ENABLE
TIM1.SourceBRKDigInputPolarity=TIM_BREAKINPUTSOURCE_POLARITY_LOW
TIM1.TIM_MasterOutputTrigger=TIM_TRGO_RESET
TIM1.TIM_MasterOutputTrigger2=TIM_TRGO2_OC5REF_RISING_OC6REF_RISING
TIM1.TIM_MasterSlaveMode=TIM_MASTERSLAVEMODE_DISABLE
TIM1.TIM_SlaveMode=TIM_SLAVEMODE_TRIGGER
TIM6.AutoReloadPreload=TIM_AUTORELOAD_PRELOAD_DISABLE
TIM6.PeriodNoDither=9999
TIM6.Prescaler=16
USART1.BaudRate=115200
USART1.VirtualMode-Asynchronous=VM_ASYNC
USART1.WordLength=WORDLENGTH_8B
USART2.BaudRate=19200
USART2.Parity=PARITY_EVEN
USART2.VirtualMode-Asynchronous=VM_ASYNC
USART2.WordLength=WORDLENGTH_9B
VP_CORDIC_VS_CORDIC.Mode=CORDIC_Activate
VP_FREERTOS_VS_CMSIS_V2.Mode=CMSIS_V2
VP_MotorControl_MC_ENABLED.Mode=Enabled
VP_SYS_VS_DBSignals.Mode=DisableDeadBatterySignals
VP_TIM1_VS_ClockSourceITR.Mode=TriggerSource_ITR1
VP_TIM1_VS_ControllerModeTrigger.Mode=Trigger Mode
VP_TIM1_VS_no_output4.Mode=PWM Generation4 No Output
VP_TIM1_VS_no_output5.Mode=PWM Generation5 No Output
VP_TIM1_VS_no_output6.Mode=PWM Generation6 No Output
VP_TIM6_VS_ClockSourceINT.Mode=Enable_Timer
board=custom

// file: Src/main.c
/* USER CODE BEGIN Header */
/**
  ******************************************************************************
  * @file           : main.c
  * @brief          : Main program body
  ******************************************************************************
  * @attention
  *
  * Copyright (c) 2023 STMicroelectronics.
  * All rights reserved.
  *
  * This software is licensed under terms that can be found in the LICENSE file
  * in the root directory of this software component.
  * If no LICENSE file comes with this software, it is provided AS-IS.
  *
  ******************************************************************************
  */
/* USER CODE END Header */
#include "main.h"
#include "cmsis_os.h"

/* USER CODE BEGIN Includes */
#include "stdio.h"
/* USER CODE END Includes */

typedef StaticTask_t osStaticThreadDef_t;

ADC_HandleTypeDef hadc1;
ADC_HandleTypeDef hadc2;
ADC_HandleTypeDef hadc3;
DMA_HandleTypeDef hdma_adc2;

CORDIC_HandleTypeDef hcordic;

I2C_HandleTypeDef hi2c1;

TIM_HandleTypeDef htim1;
TIM_HandleTypeDef htim6;
DMA_HandleTypeDef hdma_tim1_ch4;

UART_HandleTypeDef huart1;
UART_HandleTypeDef huart2;
DMA_HandleTypeDef hdma_usart1_rx;
DMA_HandleTypeDef hdma_usart1_tx;
DMA_HandleTypeDef hdma_usart2_tx;
DMA_HandleTypeDef hdma_usart2_rx;

/* Definitions for Print_Task */
osThreadId_t Print_TaskHandle;
uint32_t PrintTaskBuffer[ 256 ];
osStaticThreadDef_t PrintTaskControlBlock;
const osThreadAttr_t Print_Task_attributes = {
  .name = "Print_Task",
  .stack_mem = &PrintTaskBuffer[0],
  .stack_size = sizeof(PrintTaskBuffer),
  .cb_mem = &PrintTaskControlBlock,
  .cb_size = sizeof(PrintTaskControlBlock),
  .priority = (osPriority_t) osPriorityLow,
};
/* Definitions for Modbus_Task */
osThreadId_t Modbus_TaskHandle;
uint32_t Modbus_TaskBuffer[ 128 ];
osStaticThreadDef_t Modbus_TaskControlBlock;
const osThreadAttr_t Modbus_Task_attributes = {
  .name = "Modbus_Task",
  .stack_mem = &Modbus_TaskBuffer[0],
  .stack_size = sizeof(Modbus_TaskBuffer),
  .cb_mem = &Modbus_TaskControlBlock,
  .cb_size = sizeof(Modbus_TaskControlBlock),
  .priority = (osPriority_t) osPriorityHigh,
};
/* Definitions for Sensor_TasK */
osThreadId_t Sensor_TasKHandle;
uint32_t Sensor_TasKBuffer[ 128 ];
osStaticThreadDef_t Sensor_TasKControlBlock;
const osThreadAttr_t Sensor_TasK_attributes = {
  .name = "Sensor_TasK",
  .stack_mem = &Sensor_TasKBuffer[0],
  .stack_size = sizeof(Sensor_TasKBuffer),
  .cb_mem = &Sensor_TasKControlBlock,
  .cb_size = sizeof(Sensor_TasKControlBlock),
  .priority = (osPriority_t) osPriorityNormal,
};
/* Definitions for PowerCTRLTask */
osThreadId_t PowerCTRLTaskHandle;
uint32_t PowerCTRLTaskBuffer[ 128 ];
osStaticThreadDef_t PowerCTRLTaskControlBlock;
const osThreadAttr_t PowerCTRLTask_attributes = {
  .name = "PowerCTRLTask",
  .stack_mem = &PowerCTRLTaskBuffer[0],
  .stack_size = sizeof(PowerCTRLTaskBuffer),
  .cb_mem = &PowerCTRLTaskControlBlock,
  .cb_size = sizeof(PowerCTRLTaskControlBlock),
  .priority = (osPriority_t) osPriorityHigh,
};
/* USER CODE BEGIN PV */

uint32_t temp_adc[3];
float IPM_temp = 0;
const uint16_t Init_Ramp_Time = 60000; // msec
uint16_t ACC_Time = 30000; // msec
const float ACC_Value = 0.008; // rps(01Hz) / msec
const float Init_Ramp_Speed = 3000; //RPM

/* USER CODE END PV */

void SystemClock_Config(void);
static void MX_GPIO_Init(void);
static void MX_DMA_Init(void);
static void MX_ADC1_Init(void);
static void MX_CORDIC_Init(void);
static void MX_TIM1_Init(void);
static void MX_USART1_UART_Init(void);
static void MX_USART2_UART_Init(void);
static void MX_TIM6_Init(void);
static void MX_ADC2_Init(void);
static void MX_I2C1_Init(void);
static void MX_ADC3_Init(void);
void StartPrintTask(void *argument);
void StartModbusTask(void *argument);
void StartSensorTask(void *argument);
void StartPowerCTRLTask(void *argument);

static void MX_NVIC_Init(void);

int main(void)
{
  __disable_irq();

  /* MCU Configuration--------------------------------------------------------*/

  /* Reset of all peripherals, Initializes the Flash interface and the Systick. */
  HAL_Init();

  /* USER CODE BEGIN Init */
  FLASH_If_Init();

  HAL_RCC_DeInit();
  /* USER CODE END Init */

  /* Configure the system clock */
  SystemClock_Config();

  /* Initialize all configured peripherals */
  MX_GPIO_Init();
  MX_DMA_Init();
  MX_ADC1_Init();
  MX_CORDIC_Init();
  MX_TIM1_Init();
  MX_USART1_UART_Init();
  MX_MotorControl_Init();
  MX_USART2_UART_Init();
  MX_TIM6_Init();
  MX_ADC2_Init();
  MX_I2C1_Init();
  MX_ADC3_Init();

  /* Initialize interrupts */
  MX_NVIC_Init();
  /* USER CODE BEGIN 2 */

  /* TIM6 Initial Configuration */
  HAL_TIM_Base_Start_IT(&htim6);

  /* MC Initial Configuration */
  MCI_ExecSpeedRamp_F(&Mci[M1],Init_Ramp_Speed,Init_Ramp_Time);
  Modbus_Slave_init();

  /* ADC Initial Configuration */
  ADC2_DMA_Init((uint32_t *)temp_adc);

  /* PFC Initial Configuration */
  HAL_GPIO_WritePin(PFC_EN_GPIO_Port,PFC_EN_Pin,GPIO_PIN_RESET);

  __enable_irq();
  /* USER CODE END 2 */

  /* Init scheduler */
  osKernelInitialize();

  /* Create the thread(s) */
  /* creation of Print_Task */
  Print_TaskHandle = osThreadNew(StartPrintTask, NULL, &Print_Task_attributes);

  /* creation of Modbus_Task */
  Modbus_TaskHandle = osThreadNew(StartModbusTask, NULL, &Modbus_Task_attributes);

  /* creation of Sensor_TasK */
  Sensor_TasKHandle = osThreadNew(StartSensorTask, NULL, &Sensor_TasK_attributes);

  /* creation of PowerCTRLTask */
  PowerCTRLTaskHandle = osThreadNew(StartPowerCTRLTask, NULL, &PowerCTRLTask_attributes);

  /* Start scheduler */
  osKernelStart();

  /* We should never get here as control is now taken by the scheduler */
  /* Infinite loop */
  while (1)
  {

  }
}

void SystemClock_Config(void)
{
  RCC_OscInitTypeDef RCC_OscInitStruct = {0};
  RCC_ClkInitTypeDef RCC_ClkInitStruct = {0};

  /** Configure the main internal regulator output voltage
  */
  HAL_PWREx_ControlVoltageScaling(PWR_REGULATOR_VOLTAGE_SCALE1_BOOST);

  /** Initializes the RCC Oscillators according to the specified parameters
  * in the RCC_OscInitTypeDef structure.
  */
  RCC_OscInitStruct.OscillatorType = RCC_OSCILLATORTYPE_HSE;
  RCC_OscInitStruct.HSEState = RCC_HSE_ON;
  RCC_OscInitStruct.PLL.PLLState = RCC_PLL_ON;
  RCC_OscInitStruct.PLL.PLLSource = RCC_PLLSOURCE_HSE;
  RCC_OscInitStruct.PLL.PLLM = RCC_PLLM_DIV2;
  RCC_OscInitStruct.PLL.PLLN = 85;
  RCC_OscInitStruct.PLL.PLLP = RCC_PLLP_DIV8;
  RCC_OscInitStruct.PLL.PLLQ = RCC_PLLQ_DIV2;
  RCC_OscInitStruct.PLL.PLLR = RCC_PLLR_DIV2;
  if (HAL_RCC_OscConfig(&RCC_OscInitStruct) != HAL_OK)
  {
    Error_Handler();
  }

  /** Initializes the CPU, AHB and APB buses clocks
  */
  RCC_ClkInitStruct.ClockType = RCC_CLOCKTYPE_HCLK|RCC_CLOCKTYPE_SYSCLK
                              |RCC_CLOCKTYPE_PCLK1|RCC_CLOCKTYPE_PCLK2;
  RCC_ClkInitStruct.SYSCLKSource = RCC_SYSCLKSOURCE_PLLCLK;
  RCC_ClkInitStruct.AHBCLKDivider = RCC_SYSCLK_DIV1;
  RCC_ClkInitStruct.APB1CLKDivider = RCC_HCLK_DIV1;
  RCC_ClkInitStruct.APB2CLKDivider = RCC_HCLK_DIV1;

  if (HAL_RCC_ClockConfig(&RCC_ClkInitStruct, FLASH_LATENCY_4) != HAL_OK)
  {
    Error_Handler();
  }
}

/**
  * @brief NVIC Configuration.
  * @retval None
  */
static void MX_NVIC_Init(void)
{
  /* USART1_IRQn interrupt configuration */
  HAL_NVIC_SetPriority(USART1_IRQn, 3, 0);
  HAL_NVIC_EnableIRQ(USART1_IRQn);
  /* DMA1_Channel1_IRQn interrupt configuration */
  HAL_NVIC_SetPriority(DMA1_Channel1_IRQn, 0, 0);
  HAL_NVIC_EnableIRQ(DMA1_Channel1_IRQn);
  /* DMA1_Channel2_IRQn interrupt configuration */
  HAL_NVIC_SetPriority(DMA1_Channel2_IRQn, 3, 0);
  HAL_NVIC_EnableIRQ(DMA1_Channel2_IRQn);
  /* ADC1_2_IRQn interrupt configuration */
  HAL_NVIC_SetPriority(ADC1_2_IRQn, 2, 0);
  HAL_NVIC_EnableIRQ(ADC1_2_IRQn);
  /* TIM1_BRK_TIM15_IRQn interrupt configuration */
  HAL_NVIC_SetPriority(TIM1_BRK_TIM15_IRQn, 4, 0);
  HAL_NVIC_EnableIRQ(TIM1_BRK_TIM15_IRQn);
  /* TIM1_UP_TIM16_IRQn interrupt configuration */
  HAL_NVIC_SetPriority(TIM1_UP_TIM16_IRQn, 0, 0);
  HAL_NVIC_EnableIRQ(TIM1_UP_TIM16_IRQn);
  /* TIM6_DAC_IRQn interrupt configuration */
  HAL_NVIC_SetPriority(TIM6_DAC_IRQn, 15, 0);
  HAL_NVIC_EnableIRQ(TIM6_DAC_IRQn);
}

static void MX_ADC1_Init(void)
{

  ADC_MultiModeTypeDef multimode = {0};
  ADC_InjectionConfTypeDef sConfigInjected = {0};
  ADC_ChannelConfTypeDef sConfig = {0};

  /** Common config
  */
  hadc1.Instance = ADC1;
  hadc1.Init.ClockPrescaler = ADC_CLOCK_ASYNC_DIV1;
  hadc1.Init.Resolution = ADC_RESOLUTION_12B;
  hadc1.Init.DataAlign = ADC_DATAALIGN_LEFT;
  hadc1.Init.GainCompensation = 0;
  hadc1.Init.ScanConvMode = ADC_SCAN_ENABLE;
  hadc1.Init.EOCSelection = ADC_EOC_SINGLE_CONV;
  hadc1.Init.LowPowerAutoWait = DISABLE;
  hadc1.Init.ContinuousConvMode = DISABLE;
  hadc1.Init.NbrOfConversion = 1;
  hadc1.Init.DiscontinuousConvMode = DISABLE;
  hadc1.Init.ExternalTrigConv = ADC_SOFTWARE_START;
  hadc1.Init.ExternalTrigConvEdge = ADC_EXTERNALTRIGCONVEDGE_NONE;
  hadc1.Init.DMAContinuousRequests = DISABLE;
  hadc1.Init.Overrun = ADC_OVR_DATA_PRESERVED;
  hadc1.Init.OversamplingMode = DISABLE;
  if (HAL_ADC_Init(&hadc1) != HAL_OK)
  {
    Error_Handler();
  }

  /** Configure the ADC multi-mode
  */
  multimode.Mode = ADC_MODE_INDEPENDENT;
  if (HAL_ADCEx_MultiModeConfigChannel(&hadc1, &multimode) != HAL_OK)
  {
    Error_Handler();
  }

  /** Configure Injected Channel
  */
  sConfigInjected.InjectedChannel = ADC_CHANNEL_12;
  sConfigInjected.InjectedRank = ADC_INJECTED_RANK_1;
  sConfigInjected.InjectedSamplingTime = ADC_SAMPLETIME_6CYCLES_5;
  sConfigInjected.InjectedSingleDiff = ADC_SINGLE_ENDED;
  sConfigInjected.InjectedOffsetNumber = ADC_OFFSET_NONE;
  sConfigInjected.InjectedOffset = 0;
  sConfigInjected.InjectedNbrOfConversion = 2;
  sConfigInjected.InjectedDiscontinuousConvMode = DISABLE;
  sConfigInjected.AutoInjectedConv = DISABLE;
  sConfigInjected.QueueInjectedContext = DISABLE;
  sConfigInjected.ExternalTrigInjecConv = ADC_EXTERNALTRIGINJEC_T1_TRGO;
  sConfigInjected.ExternalTrigInjecConvEdge = ADC_EXTERNALTRIGINJECCONV_EDGE_RISINGFALLING;
  sConfigInjected.InjecOversamplingMode = DISABLE;
  if (HAL_ADCEx_InjectedConfigChannel(&hadc1, &sConfigInjected) != HAL_OK)
  {
    Error_Handler();
  }

  /** Configure Injected Channel
  */
  sConfigInjected.InjectedRank = ADC_INJECTED_RANK_2;
  if (HAL_ADCEx_InjectedConfigChannel(&hadc1, &sConfigInjected) != HAL_OK)
  {
    Error_Handler();
  }

  /** Configure Regular Channel
  */
  sConfig.Channel = ADC_CHANNEL_3;
  sConfig.Rank = ADC_REGULAR_RANK_1;
  sConfig.SamplingTime = ADC_SAMPLETIME_640CYCLES_5;
  sConfig.SingleDiff = ADC_SINGLE_ENDED;
  sConfig.OffsetNumber = ADC_OFFSET_NONE;
  sConfig.Offset = 0;
  if (HAL_ADC_ConfigChannel(&hadc1, &sConfig) != HAL_OK)
  {
    Error_Handler();
  }

}

static void MX_ADC2_Init(void)
{

  ADC_ChannelConfTypeDef sConfig = {0};

  /** Common config
  */
  hadc2.Instance = ADC2;
  hadc2.Init.ClockPrescaler = ADC_CLOCK_ASYNC_DIV1;
  hadc2.Init.Resolution = ADC_RESOLUTION_12B;
  hadc2.Init.DataAlign = ADC_DATAALIGN_RIGHT;
  hadc2.Init.GainCompensation = 0;
  hadc2.Init.ScanConvMode = ADC_SCAN_ENABLE;
  hadc2.Init.EOCSelection = ADC_EOC_SINGLE_CONV;
  hadc2.Init.LowPowerAutoWait = DISABLE;
  hadc2.Init.ContinuousConvMode = ENABLE;
  hadc2.Init.NbrOfConversion = 3;
  hadc2.Init.DiscontinuousConvMode = DISABLE;
  hadc2.Init.ExternalTrigConv = ADC_SOFTWARE_START;
  hadc2.Init.ExternalTrigConvEdge = ADC_EXTERNALTRIGCONVEDGE_NONE;
  hadc2.Init.DMAContinuousRequests = ENABLE;
  hadc2.Init.Overrun = ADC_OVR_DATA_PRESERVED;
  hadc2.Init.OversamplingMode = DISABLE;
  if (HAL_ADC_Init(&hadc2) != HAL_OK)
  {
    Error_Handler();
  }

  /** Configure Regular Channel
  */
  sConfig.Channel = ADC_CHANNEL_8;
  sConfig.Rank = ADC_REGULAR_RANK_1;
  sConfig.SamplingTime = ADC_SAMPLETIME_2CYCLES_5;
  sConfig.SingleDiff = ADC_SINGLE_ENDED;
  sConfig.OffsetNumber = ADC_OFFSET_NONE;
  sConfig.Offset = 0;
  if (HAL_ADC_ConfigChannel(&hadc2, &sConfig) != HAL_OK)
  {
    Error_Handler();
  }

  /** Configure Regular Channel
  */
  sConfig.Channel = ADC_CHANNEL_13;
  sConfig.Rank = ADC_REGULAR_RANK_2;
  if (HAL_ADC_ConfigChannel(&hadc2, &sConfig) != HAL_OK)
  {
    Error_Handler();
  }

  /** Configure Regular Channel
  */
  sConfig.Channel = ADC_CHANNEL_17;
  sConfig.Rank = ADC_REGULAR_RANK_3;
  if (HAL_ADC_ConfigChannel(&hadc2, &sConfig) != HAL_OK)
  {
    Error_Handler();
  }

}

static void MX_ADC3_Init(void)
{

  ADC_MultiModeTypeDef multimode = {0};
  ADC_ChannelConfTypeDef sConfig = {0};

  /** Common config
  */
  hadc3.Instance = ADC3;
  hadc3.Init.ClockPrescaler = ADC_CLOCK_SYNC_PCLK_DIV4;
  hadc3.Init.Resolution = ADC_RESOLUTION_12B;
  hadc3.Init.DataAlign = ADC_DATAALIGN_RIGHT;
  hadc3.Init.GainCompensation = 0;
  hadc3.Init.ScanConvMode = ADC_SCAN_DISABLE;
  hadc3.Init.EOCSelection = ADC_EOC_SINGLE_CONV;
  hadc3.Init.LowPowerAutoWait = DISABLE;
  hadc3.Init.ContinuousConvMode = DISABLE;
  hadc3.Init.NbrOfConversion = 1;
  hadc3.Init.DiscontinuousConvMode = DISABLE;
  hadc3.Init.ExternalTrigConv = ADC_SOFTWARE_START;
  hadc3.Init.ExternalTrigConvEdge = ADC_EXTERNALTRIGCONVEDGE_NONE;
  hadc3.Init.DMAContinuousRequests = DISABLE;
  hadc3.Init.Overrun = ADC_OVR_DATA_PRESERVED;
  hadc3.Init.OversamplingMode = DISABLE;
  if (HAL_ADC_Init(&hadc3) != HAL_OK)
  {
    Error_Handler();
  }

  /** Configure the ADC multi-mode
  */
  multimode.Mode = ADC_MODE_INDEPENDENT;
  if (HAL_ADCEx_MultiModeConfigChannel(&hadc3, &multimode) != HAL_OK)
  {
    Error_Handler();
  }

  /** Configure Regular Channel
  */
  sConfig.Channel = ADC_CHANNEL_1;
  sConfig.Rank = ADC_REGULAR_RANK_1;
  sConfig.SamplingTime = ADC_SAMPLETIME_2CYCLES_5;
  sConfig.SingleDiff = ADC_SINGLE_ENDED;
  sConfig.OffsetNumber = ADC_OFFSET_NONE;
  sConfig.Offset = 0;
  if (HAL_ADC_ConfigChannel(&hadc3, &sConfig) != HAL_OK)
  {
    Error_Handler();
  }

}

static void MX_CORDIC_Init(void)
{

  hcordic.Instance = CORDIC;
  if (HAL_CORDIC_Init(&hcordic) != HAL_OK)
  {
    Error_Handler();
  }

}

static void MX_I2C1_Init(void)
{

  hi2c1.Instance = I2C1;
  hi2c1.Init.Timing = 0x30A0A7FB;
  hi2c1.Init.OwnAddress1 = 0;
  hi2c1.Init.AddressingMode = I2C_ADDRESSINGMODE_7BIT;
  hi2c1.Init.DualAddressMode = I2C_DUALADDRESS_DISABLE;
  hi2c1.Init.OwnAddress2 = 0;
  hi2c1.Init.OwnAddress2Masks = I2C_OA2_NOMASK;
  hi2c1.Init.GeneralCallMode = I2C_GENERALCALL_DISABLE;
  hi2c1.Init.NoStretchMode = I2C_NOSTRETCH_DISABLE;
  if (HAL_I2C_Init(&hi2c1) != HAL_OK)
  {
    Error_Handler();
  }

  /** Configure Analogue filter
  */
  if (HAL_I2CEx_ConfigAnalogFilter(&hi2c1, I2C_ANALOGFILTER_ENABLE) != HAL_OK)
  {
    Error_Handler();
  }

  /** Configure Digital filter
  */
  if (HAL_I2CEx_ConfigDigitalFilter(&hi2c1, 0) != HAL_OK)
  {
    Error_Handler();
  }

}

static void MX_TIM1_Init(void)
{

  TIM_SlaveConfigTypeDef sSlaveConfig = {0};
  TIM_MasterConfigTypeDef sMasterConfig = {0};
  TIMEx_BreakInputConfigTypeDef sBreakInputConfig = {0};
  TIM_OC_InitTypeDef sConfigOC = {0};
  TIM_BreakDeadTimeConfigTypeDef sBreakDeadTimeConfig = {0};

  htim1.Instance = TIM1;
  htim1.Init.Prescaler = ((TIM_CLOCK_DIVIDER) - 1);
  htim1.Init.CounterMode = TIM_COUNTERMODE_CENTERALIGNED2;
  htim1.Init.Period = ((PWM_PERIOD_CYCLES) / 2);
  htim1.Init.ClockDivision = TIM_CLOCKDIVISION_DIV2;
  htim1.Init.RepetitionCounter = (REP_COUNTER);
  htim1.Init.AutoReloadPreload = TIM_AUTORELOAD_PRELOAD_DISABLE;
  if (HAL_TIM_Base_Init(&htim1) != HAL_OK)
  {
    Error_Handler();
  }
  if (HAL_TIM_PWM_Init(&htim1) != HAL_OK)
  {
    Error_Handler();
  }
  sSlaveConfig.SlaveMode = TIM_SLAVEMODE_TRIGGER;
  sSlaveConfig.InputTrigger = TIM_TS_ITR1;
  if (HAL_TIM_SlaveConfigSynchro(&htim1, &sSlaveConfig) != HAL_OK)
  {
    Error_Handler();
  }
  sMasterConfig.MasterOutputTrigger = TIM_TRGO_RESET;
  sMasterConfig.MasterOutputTrigger2 = TIM_TRGO2_OC5REF_RISING_OC6REF_RISING;
  sMasterConfig.MasterSlaveMode = TIM_MASTERSLAVEMODE_DISABLE;
  if (HAL_TIMEx_MasterConfigSynchronization(&htim1, &sMasterConfig) != HAL_OK)
  {
    Error_Handler();
  }
  sBreakInputConfig.Source = TIM_BREAKINPUTSOURCE_BKIN;
  sBreakInputConfig.Enable = TIM_BREAKINPUTSOURCE_ENABLE;
  sBreakInputConfig.Polarity = TIM_BREAKINPUTSOURCE_POLARITY_LOW;
  if (HAL_TIMEx_ConfigBreakInput(&htim1, TIM_BREAKINPUT_BRK, &sBreakInputConfig) != HAL_OK)
  {
    Error_Handler();
  }
  sConfigOC.OCMode = TIM_OCMODE_PWM1;
  sConfigOC.Pulse = ((PWM_PERIOD_CYCLES) / 4);
  sConfigOC.OCPolarity = TIM_OCPOLARITY_HIGH;
  sConfigOC.OCNPolarity = TIM_OCNPOLARITY_HIGH;
  sConfigOC.OCFastMode = TIM_OCFAST_DISABLE;
  sConfigOC.OCIdleState = TIM_OCIDLESTATE_RESET;
  sConfigOC.OCNIdleState = TIM_OCNIDLESTATE_RESET;
  if (HAL_TIM_PWM_ConfigChannel(&htim1, &sConfigOC, TIM_CHANNEL_1) != HAL_OK)
  {
    Error_Handler();
  }
  if (HAL_TIM_PWM_ConfigChannel(&htim1, &sConfigOC, TIM_CHANNEL_2) != HAL_OK)
  {
    Error_Handler();
  }
  if (HAL_TIM_PWM_ConfigChannel(&htim1, &sConfigOC, TIM_CHANNEL_3) != HAL_OK)
  {
    Error_Handler();
  }
  sConfigOC.OCMode = TIM_OCMODE_PWM2;
  sConfigOC.Pulse = (((PWM_PERIOD_CYCLES) / 2) - (HTMIN));
  if (HAL_TIM_PWM_ConfigChannel(&htim1, &sConfigOC, TIM_CHANNEL_4) != HAL_OK)
  {
    Error_Handler();
  }
  sConfigOC.Pulse = (((PWM_PERIOD_CYCLES) / 2) + 1);
  if (HAL_TIM_PWM_ConfigChannel(&htim1, &sConfigOC, TIM_CHANNEL_5) != HAL_OK)
  {
    Error_Handler();
  }
  if (HAL_TIM_PWM_ConfigChannel(&htim1, &sConfigOC, TIM_CHANNEL_6) != HAL_OK)
  {
    Error_Handler();
  }
  sBreakDeadTimeConfig.OffStateRunMode = TIM_OSSR_ENABLE;
  sBreakDeadTimeConfig.OffStateIDLEMode = TIM_OSSI_ENABLE;
  sBreakDeadTimeConfig.LockLevel = TIM_LOCKLEVEL_OFF;
  sBreakDeadTimeConfig.DeadTime = ((DEAD_TIME_COUNTS) / 2);
  sBreakDeadTimeConfig.BreakState = TIM_BREAK_ENABLE;
  sBreakDeadTimeConfig.BreakPolarity = TIM_BREAKPOLARITY_HIGH;
  sBreakDeadTimeConfig.BreakFilter = 3;
  sBreakDeadTimeConfig.BreakAFMode = TIM_BREAK_AFMODE_INPUT;
  sBreakDeadTimeConfig.Break2State = TIM_BREAK2_DISABLE;
  sBreakDeadTimeConfig.Break2Polarity = TIM_BREAK2POLARITY_HIGH;
  sBreakDeadTimeConfig.Break2Filter = 3;
  sBreakDeadTimeConfig.Break2AFMode = TIM_BREAK_AFMODE_INPUT;
  sBreakDeadTimeConfig.AutomaticOutput = TIM_AUTOMATICOUTPUT_DISABLE;
  if (HAL_TIMEx_ConfigBreakDeadTime(&htim1, &sBreakDeadTimeConfig) != HAL_OK)
  {
    Error_Handler();
  }
  HAL_TIM_MspPostInit(&htim1);

}

static void MX_TIM6_Init(void)
{

  TIM_MasterConfigTypeDef sMasterConfig = {0};

  htim6.Instance = TIM6;
  htim6.Init.Prescaler = 16;
  htim6.Init.CounterMode = TIM_COUNTERMODE_UP;
  htim6.Init.Period = 9999;
  htim6.Init.AutoReloadPreload = TIM_AUTORELOAD_PRELOAD_DISABLE;
  if (HAL_TIM_Base_Init(&htim6) != HAL_OK)
  {
    Error_Handler();
  }
  sMasterConfig.MasterOutputTrigger = TIM_TRGO_RESET;
  sMasterConfig.MasterSlaveMode = TIM_MASTERSLAVEMODE_DISABLE;
  if (HAL_TIMEx_MasterConfigSynchronization(&htim6, &sMasterConfig) != HAL_OK)
  {
    Error_Handler();
  }

}

static void MX_USART1_UART_Init(void)
{

  huart1.Instance = USART1;
  huart1.Init.BaudRate = 115200;
  huart1.Init.WordLength = UART_WORDLENGTH_8B;
  huart1.Init.StopBits = UART_STOPBITS_1;
  huart1.Init.Parity = UART_PARITY_NONE;
  huart1.Init.Mode = UART_MODE_TX_RX;
  huart1.Init.HwFlowCtl = UART_HWCONTROL_NONE;
  huart1.Init.OverSampling = UART_OVERSAMPLING_16;
  huart1.Init.OneBitSampling = UART_ONE_BIT_SAMPLE_DISABLE;
  huart1.Init.ClockPrescaler = UART_PRESCALER_DIV1;
  huart1.AdvancedInit.AdvFeatureInit = UART_ADVFEATURE_NO_INIT;
  if (HAL_UART_Init(&huart1) != HAL_OK)
  {
    Error_Handler();
  }
  if (HAL_UARTEx_SetTxFifoThreshold(&huart1, UART_TXFIFO_THRESHOLD_1_8) != HAL_OK)
  {
    Error_Handler();
  }
  if (HAL_UARTEx_SetRxFifoThreshold(&huart1, UART_RXFIFO_THRESHOLD_1_8) != HAL_OK)
  {
    Error_Handler();
  }
  if (HAL_UARTEx_DisableFifoMode(&huart1) != HAL_OK)
  {
    Error_Handler();
  }

}

static void MX_USART2_UART_Init(void)
{

  huart2.Instance = USART2;
  huart2.Init.BaudRate = 19200;
  huart2.Init.WordLength = UART_WORDLENGTH_9B;
  huart2.Init.StopBits = UART_STOPBITS_1;
  huart2.Init.Parity = UART_PARITY_EVEN;
  huart2.Init.Mode = UART_MODE_TX_RX;
  huart2.Init.HwFlowCtl = UART_HWCONTROL_NONE;
  huart2.Init.OverSampling = UART_OVERSAMPLING_16;
  huart2.Init.OneBitSampling = UART_ONE_BIT_SAMPLE_DISABLE;
  huart2.Init.ClockPrescaler = UART_PRESCALER_DIV1;
  huart2.AdvancedInit.AdvFeatureInit = UART_ADVFEATURE_NO_INIT;
  if (HAL_UART_Init(&huart2) != HAL_OK)
  {
    Error_Handler();
  }
  if (HAL_UARTEx_SetTxFifoThreshold(&huart2, UART_TXFIFO_THRESHOLD_1_8) != HAL_OK)
  {
    Error_Handler();
  }
  if (HAL_UARTEx_SetRxFifoThreshold(&huart2, UART_RXFIFO_THRESHOLD_1_8) != HAL_OK)
  {
    Error_Handler();
  }
  if (HAL_UARTEx_DisableFifoMode(&huart2) != HAL_OK)
  {
    Error_Handler();
  }

}

static void MX_DMA_Init(void)
{

  /* DMA controller clock enable */
  __HAL_RCC_DMAMUX1_CLK_ENABLE();
  __HAL_RCC_DMA1_CLK_ENABLE();

  /* DMA interrupt init */
  /* DMA1_Channel4_IRQn interrupt configuration */
  HAL_NVIC_SetPriority(DMA1_Channel4_IRQn, 3, 0);
  HAL_NVIC_EnableIRQ(DMA1_Channel4_IRQn);
  /* DMA1_Channel5_IRQn interrupt configuration */
  HAL_NVIC_SetPriority(DMA1_Channel5_IRQn, 3, 0);
  HAL_NVIC_EnableIRQ(DMA1_Channel5_IRQn);

}

static void MX_GPIO_Init(void)
{
  GPIO_InitTypeDef GPIO_InitStruct = {0};

  /* GPIO Ports Clock Enable */
  __HAL_RCC_GPIOC_CLK_ENABLE();
  __HAL_RCC_GPIOF_CLK_ENABLE();
  __HAL_RCC_GPIOA_CLK_ENABLE();
  __HAL_RCC_GPIOB_CLK_ENABLE();
  __HAL_RCC_GPIOD_CLK_ENABLE();

  /*Configure GPIO pin Output Level */
  HAL_GPIO_WritePin(GPIOC, DEBUG_LED_RED_Pin|DEBUG_LED_GREEN_Pin|U1_DIR_Pin, GPIO_PIN_RESET);

  /*Configure GPIO pin Output Level */
  HAL_GPIO_WritePin(PFC_EN_GPIO_Port, PFC_EN_Pin, GPIO_PIN_RESET);

  /*Configure GPIO pin Output Level */
  HAL_GPIO_WritePin(U2_DIR_GPIO_Port, U2_DIR_Pin, GPIO_PIN_RESET);

  /*Configure GPIO pins : DEBUG_LED_RED_Pin DEBUG_LED_GREEN_Pin U1_DIR_Pin */
  GPIO_InitStruct.Pin = DEBUG_LED_RED_Pin|DEBUG_LED_GREEN_Pin|U1_DIR_Pin;
  GPIO_InitStruct.Mode = GPIO_MODE_OUTPUT_PP;
  GPIO_InitStruct.Pull = GPIO_NOPULL;
  GPIO_InitStruct.Speed = GPIO_SPEED_FREQ_LOW;
  HAL_GPIO_Init(GPIOC, &GPIO_InitStruct);

  /*Configure GPIO pin : PFC_EN_Pin */
  GPIO_InitStruct.Pin = PFC_EN_Pin;
  GPIO_InitStruct.Mode = GPIO_MODE_OUTPUT_PP;
  GPIO_InitStruct.Pull = GPIO_NOPULL;
  GPIO_InitStruct.Speed = GPIO_SPEED_FREQ_LOW;
  HAL_GPIO_Init(PFC_EN_GPIO_Port, &GPIO_InitStruct);

  /*Configure GPIO pin : U2_DIR_Pin */
  GPIO_InitStruct.Pin = U2_DIR_Pin;
  GPIO_InitStruct.Mode = GPIO_MODE_OUTPUT_PP;
  GPIO_InitStruct.Pull = GPIO_NOPULL;
  GPIO_InitStruct.Speed = GPIO_SPEED_FREQ_LOW;
  HAL_GPIO_Init(U2_DIR_GPIO_Port, &GPIO_InitStruct);

}

__weak void StartPrintTask(void *argument)
{
}

__weak void StartModbusTask(void *argument)
{
}

__weak void StartSensorTask(void *argument)
{
  for(;;)
  {
    osDelay(1);
  }
}

__weak void StartPowerCTRLTask(void *argument)
{
  for(;;)
  {
    osDelay(1);
  }
}

void Error_Handler(void)
{
  /* USER CODE BEGIN Error_Handler_Debug */
  /* User can add his own implementation to report the HAL error return state */
  __disable_irq();
  while (1)
  {
    // printf("Error_Hanler Disable irq. \n");
    HAL_Delay(1000);
  }
  /* USER CODE END Error_Handler_Debug */
}

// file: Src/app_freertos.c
/* USER CODE BEGIN Header */
/**
  ******************************************************************************
  * File Name          : app_freertos.c
  * Description        : Code for freertos applications
  ******************************************************************************
  * @attention
  *
  * Copyright (c) 2024 STMicroelectronics.
  * All rights reserved.
  *
  * This software is licensed under terms that can be found in the LICENSE file
  * in the root directory of this software component.
  * If no LICENSE file comes with this software, it is provided AS-IS.
  *
  ******************************************************************************
  */
/* USER CODE END Header */

#include "FreeRTOS.h"
#include "task.h"
#include "main.h"

/* USER CODE BEGIN Includes */
#include "cmsis_os.h"
#include "math.h"
#include "app_System_Protect.h"
/* USER CODE END Includes */

/* USER CODE BEGIN Variables */
#ifdef DEBUG
const uint8_t UserAppId[16] = "D E B U G 0 0 1\0";
#endif
#ifdef VER6
const uint8_t UserAppId[16] = "R E A L S E 0 6\0";
#endif
#ifdef VER7
const uint8_t UserAppId[16] = "R E A L S E 0 7\0";
#endif
#ifdef VER8
const uint8_t UserAppId[16] = "R E A L S E 0 8\0";
#endif
#ifdef VER9
const uint8_t UserAppId[16] = "R E A L S E 0 9\0";
#endif
float PFC_voltage_rms = 0.0;
float PFC_current_rms = 0.0;
float PFC_power = 0.0;
uint16_t sec = 0;
uint16_t Curr_adc[ADC_BUFFER_SIZE] = {0};
float Error_buffer[ERROR_BUFFER_SIZE] = {0.0};
float Current_Speed;
float Speed_Target;
uint32_t OneShunt_ADC = 0;
/* USER CODE END Variables */

/* USER CODE BEGIN FunctionPrototypes */
void Logging_ADCvalue(ADC_HandleTypeDef hadc, uint16_t buffer[], uint16_t size);
void Logging_ADCvalue(ADC_HandleTypeDef hadc, uint16_t buffer[], uint16_t size)
{
  if (HAL_ADC_Start(&hadc) != HAL_OK)
  {
    // Handle ADC start error
    Error_Handler();
  }
    // Poll for ADC conversion to be completed
  if (HAL_ADC_PollForConversion(&hadc, HAL_MAX_DELAY) == HAL_OK)
  {
    static uint32_t i = 0 ;
    buffer[i++] = HAL_ADC_GetValue(&hadc);
    if(i > size - 1)
    {
      i = 0;
    }
  }
}
void Logging_SpeedErr();
void Logging_SpeedErr()
{
    MCI_State_t state = MCI_GetSTMState(&Mci[M1]);
    static uint32_t i = 0;

    if(state == RUN)
    {
        Error_buffer[i++] = Speed_Target - Current_Speed;
        if(i == ERROR_BUFFER_SIZE -1)
        {
            i = 0;
        }
    }
}
/* USER CODE END FunctionPrototypes */

/* Hook prototypes */
void vApplicationStackOverflowHook(xTaskHandle xTask, signed char *pcTaskName);

/* USER CODE BEGIN 4 */
void vApplicationStackOverflowHook(xTaskHandle xTask, signed char *pcTaskName)
{
   /* Run time stack overflow checking is performed if
   configCHECK_FOR_STACK_OVERFLOW is defined to 1 or 2. This hook function is
   called if a stack overflow is detected. */
}
/* USER CODE END 4 */

/* USER CODE BEGIN Application */
/* USER CODE BEGIN Header_StartPrintTask */
/**
  * @brief  Function implementing the Print_Task thread.
  * @param  argument: Not used
  * @retval None
  */
/* USER CODE END Header_StartPrintTask */
void StartPrintTask(void *argument)
{
  /* USER CODE BEGIN 5 */

  /* Infinite loop */
  for(;;)
  {
    osDelay(1000);

    qd_f_t Iqd_ref = MC_GetIqdrefMotor1_F();
    qd_f_t Iqd = MC_GetIqdMotor1_F();
    int16_t Phase_Peak_S16A = MCI_GetPhaseCurrentAmplitude(&Mci[M1]);
    float Current_Amp = (Phase_Peak_S16A * 3.3) / (65536 * RSHUNT * AMPLIFICATION_GAIN);
    Current_Speed = MC_GetAverageMecSpeedMotor1_F();
    Speed_Target = MC_GetMecSpeedReferenceMotor1_F();
    printf("\n\nRamp Speed Target : %d. ", (int)MC_GetLastRampFinalSpeedM1_F());
    printf("Ramp Command Completed: %d.\n\n", MC_HasRampCompletedMotor1());
    printf("Motor Power : %d, ",(int)MC_GetAveragePowerMotor1_F());
    printf("PFC power : %d, ",(int)PFC_power);
    printf("IPM TEMP : %u.\n\n", (uint8_t)IPM_temp);
    printf("Current Speed : %d, ", (int)Current_Speed);
    printf("Speed Target : %d.\n\n", (int)Speed_Target);
    printf("PFC voltage adc : %d. PFC current adc : %d.\n\n", (int)temp_adc[2], (int)temp_adc[1]);
    sprintf(float_buffer, "Iq_ref : %.2f, Iq : %.2f, Ia_pk : %.1f.\n\nId_ref : %.2f, Id : %.2f.\n\nPFC current rms : %.2f\n\n"
    , Iqd_ref.q, Iqd.q, Current_Amp, Iqd_ref.d, Iqd.d, PFC_current_rms);
    printf(float_buffer);
    printf("Alarm Fault1 : %04x\n\n",Alarm.Fault1.All);
    printf("-- Run time : %u, App ID : %s --\n\n", sec+=1, UserAppId);

    modbus_slave_value_update();
    System_Alarm_Handler();
  }
  /* USER CODE END 5 */
}

/* USER CODE BEGIN Header_StartModbusTask */
/**
* @brief Function implementing the Modbus_Task thread.
* @param argument: Not used
* @retval None
*/
/* USER CODE END Header_StartModbusTask */
void StartModbusTask(void *argument)
{
  /* USER CODE BEGIN StartModbusTask */
  /* Infinite loop */
  for(;;)
  {
    osDelay(1);
    /* Enable UART */
    detect_uart();

  }
  /* USER CODE END StartModbusTask */
}

/* USER CODE BEGIN Header_StartSensorTask */
/**
* @brief Function implementing the StartSensorTask thread.
* @param argument: Not used
* @retval None
*/
/* USER CODE END Header_StartSensorTask */
void StartSensorTask(void *argument)
{
  /* USER CODE BEGIN StartSensorTask */
  /* Infinite loop */
  for(;;)
  {
    osDelay(1);

    Temp_Average(temp_adc[0], &IPM_temp);

    PFC_GetRMS();

    OneShunt_ADC = HAL_ADC_GetValue(&hadc3);

    Logging_SpeedErr();

    OutputLosePhase();

    DCunderVoltage();
    DCoverVoltage();
    ADCoffsetAbnormal();
  }
  /* USER CODE END StartSensorTask */
}

void StartPowerCTRLTask(void *argument)
{
  /* USER CODE BEGIN StartPowerCTRLTask */
  /* Infinite loop */
  for(;;)
  {
    osDelay(500);

    PowerLimitControl();
  }
  /* USER CODE END StartPowerCTRLTask */
}
/* USER CODE END Application */
